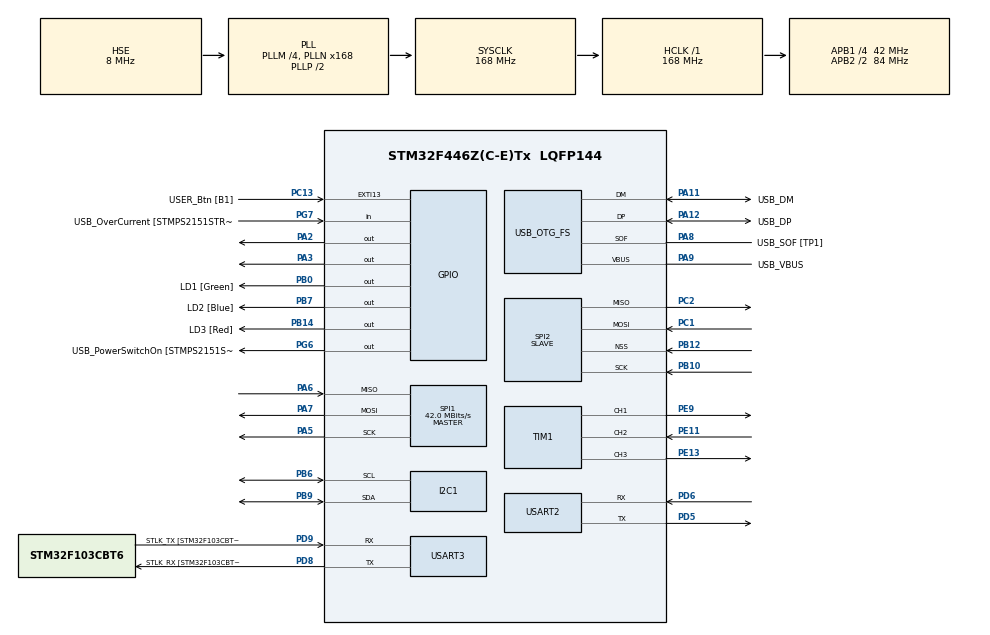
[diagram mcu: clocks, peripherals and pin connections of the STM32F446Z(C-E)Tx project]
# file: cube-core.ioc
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Dma.I2C1_RX.0.Direction=DMA_PERIPH_TO_MEMORY
Dma.I2C1_RX.0.FIFOMode=DMA_FIFOMODE_DISABLE
Dma.I2C1_RX.0.Instance=DMA1_Stream0
Dma.I2C1_RX.0.MemDataAlignment=DMA_MDATAALIGN_BYTE
Dma.I2C1_RX.0.MemInc=DMA_MINC_ENABLE
Dma.I2C1_RX.0.Mode=DMA_NORMAL
Dma.I2C1_RX.0.PeriphDataAlignment=DMA_PDATAALIGN_BYTE
Dma.I2C1_RX.0.PeriphInc=DMA_PINC_DISABLE
Dma.I2C1_RX.0.Priority=DMA_PRIORITY_LOW
Dma.I2C1_TX.1.Direction=DMA_MEMORY_TO_PERIPH
Dma.I2C1_TX.1.FIFOMode=DMA_FIFOMODE_DISABLE
Dma.I2C1_TX.1.Instance=DMA1_Stream7
Dma.I2C1_TX.1.MemDataAlignment=DMA_MDATAALIGN_BYTE
Dma.I2C1_TX.1.MemInc=DMA_MINC_ENABLE
Dma.I2C1_TX.1.Mode=DMA_NORMAL
Dma.I2C1_TX.1.PeriphDataAlignment=DMA_PDATAALIGN_BYTE
Dma.I2C1_TX.1.PeriphInc=DMA_PINC_DISABLE
Dma.I2C1_TX.1.Priority=DMA_PRIORITY_LOW
Dma.Request0=I2C1_RX
Dma.Request1=I2C1_TX
Dma.Request2=SPI1_RX
Dma.Request3=SPI1_TX
Dma.Request4=SPI2_RX
Dma.Request5=SPI2_TX
Dma.Request6=USART2_RX
Dma.Request7=USART2_TX
Dma.SPI1_RX.2.Direction=DMA_PERIPH_TO_MEMORY
Dma.SPI1_RX.2.FIFOMode=DMA_FIFOMODE_DISABLE
Dma.SPI1_RX.2.Instance=DMA2_Stream0
Dma.SPI1_RX.2.MemDataAlignment=DMA_MDATAALIGN_BYTE
Dma.SPI1_RX.2.MemInc=DMA_MINC_ENABLE
Dma.SPI1_RX.2.Mode=DMA_NORMAL
Dma.SPI1_RX.2.PeriphDataAlignment=DMA_PDATAALIGN_BYTE
Dma.SPI1_RX.2.PeriphInc=DMA_PINC_DISABLE
Dma.SPI1_RX.2.Priority=DMA_PRIORITY_LOW
Dma.SPI1_TX.3.Direction=DMA_MEMORY_TO_PERIPH
Dma.SPI1_TX.3.FIFOMode=DMA_FIFOMODE_DISABLE
Dma.SPI1_TX.3.Instance=DMA2_Stream3
Dma.SPI1_TX.3.MemDataAlignment=DMA_MDATAALIGN_BYTE
Dma.SPI1_TX.3.MemInc=DMA_MINC_ENABLE
Dma.SPI1_TX.3.Mode=DMA_NORMAL
Dma.SPI1_TX.3.PeriphDataAlignment=DMA_PDATAALIGN_BYTE
Dma.SPI1_TX.3.PeriphInc=DMA_PINC_DISABLE
Dma.SPI1_TX.3.Priority=DMA_PRIORITY_LOW
Dma.SPI2_RX.4.Direction=DMA_PERIPH_TO_MEMORY
Dma.SPI2_RX.4.FIFOMode=DMA_FIFOMODE_DISABLE
Dma.SPI2_RX.4.Instance=DMA1_Stream3
Dma.SPI2_RX.4.MemDataAlignment=DMA_MDATAALIGN_BYTE
Dma.SPI2_RX.4.MemInc=DMA_MINC_ENABLE
Dma.SPI2_RX.4.Mode=DMA_NORMAL
Dma.SPI2_RX.4.PeriphDataAlignment=DMA_PDATAALIGN_BYTE
Dma.SPI2_RX.4.PeriphInc=DMA_PINC_DISABLE
Dma.SPI2_RX.4.Priority=DMA_PRIORITY_LOW
Dma.SPI2_TX.5.Direction=DMA_MEMORY_TO_PERIPH
Dma.SPI2_TX.5.FIFOMode=DMA_FIFOMODE_DISABLE
Dma.SPI2_TX.5.Instance=DMA1_Stream4
Dma.SPI2_TX.5.MemDataAlignment=DMA_MDATAALIGN_BYTE
Dma.SPI2_TX.5.MemInc=DMA_MINC_ENABLE
Dma.SPI2_TX.5.Mode=DMA_NORMAL
Dma.SPI2_TX.5.PeriphDataAlignment=DMA_PDATAALIGN_BYTE
Dma.SPI2_TX.5.PeriphInc=DMA_PINC_DISABLE
Dma.SPI2_TX.5.Priority=DMA_PRIORITY_LOW
Dma.USART2_RX.6.Direction=DMA_PERIPH_TO_MEMORY
Dma.USART2_RX.6.FIFOMode=DMA_FIFOMODE_DISABLE
Dma.USART2_RX.6.Instance=DMA1_Stream5
Dma.USART2_RX.6.MemDataAlignment=DMA_MDATAALIGN_BYTE
Dma.USART2_RX.6.MemInc=DMA_MINC_ENABLE
Dma.USART2_RX.6.Mode=DMA_NORMAL
Dma.USART2_RX.6.PeriphDataAlignment=DMA_PDATAALIGN_BYTE
Dma.USART2_RX.6.PeriphInc=DMA_PINC_DISABLE
Dma.USART2_RX.6.Priority=DMA_PRIORITY_LOW
Dma.USART2_TX.7.Direction=DMA_MEMORY_TO_PERIPH
Dma.USART2_TX.7.FIFOMode=DMA_FIFOMODE_DISABLE
Dma.USART2_TX.7.Instance=DMA1_Stream6
Dma.USART2_TX.7.MemDataAlignment=DMA_MDATAALIGN_BYTE
Dma.USART2_TX.7.MemInc=DMA_MINC_ENABLE
Dma.USART2_TX.7.Mode=DMA_NORMAL
Dma.USART2_TX.7.PeriphDataAlignment=DMA_PDATAALIGN_BYTE
Dma.USART2_TX.7.PeriphInc=DMA_PINC_DISABLE
Dma.USART2_TX.7.Priority=DMA_PRIORITY_LOW
FREERTOS.Tasks01=defaultTask,24,3000,StartDefaultTask,Default,NULL,Static,defaultTaskBuffer,defaultTaskControlBlock;myTask02,24,3000,StartTask02,Default,NULL,Static,myTask02Buffer,myTask02ControlBlock
Mcu.Family=STM32F4
Mcu.Name=STM32F446Z(C-E)Tx
Mcu.Package=LQFP144
NVIC.DMA1_Stream0_IRQn=true\:5\:0\:false\:false\:true\:true\:false\:true
NVIC.DMA1_Stream3_IRQn=true\:5\:0\:false\:false\:true\:true\:false\:true
NVIC.DMA1_Stream4_IRQn=true\:5\:0\:false\:false\:true\:true\:false\:true
NVIC.DMA1_Stream5_IRQn=true\:5\:0\:false\:false\:true\:true\:false\:true
NVIC.DMA1_Stream6_IRQn=true\:5\:0\:false\:false\:true\:true\:false\:true
NVIC.DMA1_Stream7_IRQn=true\:5\:0\:false\:false\:true\:false\:false\:true
NVIC.DMA2_Stream0_IRQn=true\:5\:0\:false\:false\:true\:true\:false\:true
NVIC.DMA2_Stream3_IRQn=true\:5\:0\:false\:false\:true\:true\:false\:true
NVIC.I2C1_EV_IRQn=true\:5\:0\:false\:false\:true\:true\:true\:true
NVIC.PriorityGroup=NVIC_PRIORITYGROUP_4
NVIC.SPI1_IRQn=true\:5\:0\:false\:false\:true\:true\:true\:true
NVIC.SPI2_IRQn=true\:5\:0\:false\:false\:true\:true\:true\:true
NVIC.TIM1_CC_IRQn=true\:5\:0\:false\:false\:true\:true\:true\:true
NVIC.TIM1_UP_TIM10_IRQn=true\:5\:0\:false\:false\:true\:true\:true\:true
NVIC.TIM8_BRK_TIM12_IRQn=true\:0\:0\:false\:false\:true\:false\:false\:true
NVIC.TimeBase=TIM8_BRK_TIM12_IRQn
NVIC.TimeBaseIP=TIM12
NVIC.USART2_IRQn=true\:5\:0\:false\:false\:true\:true\:true\:true
NVIC.USART3_IRQn=true\:5\:0\:false\:false\:true\:true\:true\:true
PA10.GPIO_Label=USB_ID
PA10.Signal=USB_OTG_FS_ID
PA11.GPIO_Label=USB_DM
PA11.Mode=Device_Only
PA11.Signal=USB_OTG_FS_DM
PA12.GPIO_Label=USB_DP
PA12.Mode=Device_Only
PA12.Signal=USB_OTG_FS_DP
PA13.GPIO_Label=TMS
PA13.Mode=Serial_Wire
PA13.Signal=SYS_JTMS-SWDIO
PA14.GPIO_Label=TCK
PA14.Mode=Serial_Wire
PA14.Signal=SYS_JTCK-SWCLK
PA2.Signal=GPIO_Output
PA3.Signal=GPIO_Output
PA5.Mode=Full_Duplex_Master
PA5.Signal=SPI1_SCK
PA6.Mode=Full_Duplex_Master
PA6.Signal=SPI1_MISO
PA7.Mode=Full_Duplex_Master
PA7.Signal=SPI1_MOSI
PA8.GPIO_Label=USB_SOF [TP1]
PA8.Mode=Activate_SOF_FS
PA8.Signal=USB_OTG_FS_SOF
PA9.GPIO_Label=USB_VBUS
PA9.Mode=Activate_VBUS
PA9.Signal=USB_OTG_FS_VBUS
PB0.GPIO_Label=LD1 [Green]
PB0.Signal=GPIO_Output
PB10.Mode=Full_Duplex_Slave
PB10.Signal=SPI2_SCK
PB12.Mode=NSS_Signal_Hard_Input
PB12.Signal=SPI2_NSS
PB14.GPIO_Label=LD3 [Red]
PB14.Signal=GPIO_Output
PB6.Mode=I2C
PB6.Signal=I2C1_SCL
PB7.GPIO_Label=LD2 [Blue]
PB7.Signal=GPIO_Output
PB9.Mode=I2C
PB9.Signal=I2C1_SDA
PC1.Mode=Full_Duplex_Slave
PC1.Signal=SPI2_MOSI
PC13.GPIO_Label=USER_Btn [B1]
PC13.Signal=GPXTI13
PC14-OSC32_IN.Mode=LSE-External-Oscillator
PC14-OSC32_IN.Signal=RCC_OSC32_IN
PC15-OSC32_OUT.Mode=LSE-External-Oscillator
PC15-OSC32_OUT.Signal=RCC_OSC32_OUT
PC2.Mode=Full_Duplex_Slave
PC2.Signal=SPI2_MISO
PD5.Mode=Asynchronous
PD5.Signal=USART2_TX
PD6.Mode=Asynchronous
PD6.Signal=USART2_RX
PD8.GPIO_Label=STLK_RX [STM32F103CBT6_PA3]
PD8.Mode=Asynchronous
PD8.Signal=USART3_TX
PD9.GPIO_Label=STLK_TX [STM32F103CBT6_PA2]
PD9.Mode=Asynchronous
PD9.Signal=USART3_RX
PE11.Signal=S_TIM1_CH2
PE13.Signal=S_TIM1_CH3
PE9.Signal=S_TIM1_CH1
PG6.GPIO_Label=USB_PowerSwitchOn [STMPS2151STR_EN]
PG6.Signal=GPIO_Output
PG7.GPIO_Label=USB_OverCurrent [STMPS2151STR_FAULT]
PG7.Signal=GPIO_Input
PH0-OSC_IN.GPIO_Label=MCO [STM32F103CBT6_PA8]
PH0-OSC_IN.Mode=HSE-External-Clock-Source
PH0-OSC_IN.Signal=RCC_OSC_IN
PH1-OSC_OUT.Mode=HSE-External-Clock-Source
PH1-OSC_OUT.Signal=RCC_OSC_OUT
ProjectManager.HeapSize=0x200
ProjectManager.StackSize=0x400
ProjectManager.TargetToolchain=Makefile
RCC.48MHZClocksFreq_Value=24000000
RCC.AHBFreq_Value=168000000
RCC.APB1CLKDivider=RCC_HCLK_DIV4
RCC.APB1Freq_Value=42000000
RCC.APB1TimFreq_Value=84000000
RCC.APB2CLKDivider=RCC_HCLK_DIV2
RCC.APB2Freq_Value=84000000
RCC.APB2TimFreq_Value=168000000
RCC.CortexFreq_Value=168000000
RCC.HCLKFreq_Value=168000000
RCC.HSE_VALUE=8000000
RCC.HSI_VALUE=16000000
RCC.PLLM=4
RCC.PLLMUL=RCC_PLL_MUL9
RCC.PLLN=168
RCC.PLLQ=7
RCC.PRESCALERUSB=RCC_USBCLKSOURCE_PLL_DIV1_5
RCC.SYSCLKFreq_VALUE=168000000
RCC.SYSCLKSource=RCC_SYSCLKSOURCE_PLLCLK
RCC.SYSCLKSourceVirtual=RCC_SYSCLKSOURCE_PLLCLK
RCC.USBFreq_Value=48000000
RCC.VCOOutputFreq_Value=336000000
SH.S_TIM1_CH1.0=TIM1_CH1,PWM Generation1 CH1
SH.S_TIM1_CH2.0=TIM1_CH2,Input_Capture2_from_TI2
SH.S_TIM1_CH3.0=TIM1_CH3,PWM Generation3 CH3
SPI1.CalculateBaudRate=42.0 MBits/s
SPI1.Direction=SPI_DIRECTION_2LINES
SPI1.FirstBit=SPI_FIRSTBIT_MSB
SPI1.Mode=SPI_MODE_MASTER
SPI1.VirtualType=VM_MASTER
SPI2.Direction=SPI_DIRECTION_2LINES
SPI2.Mode=SPI_MODE_SLAVE
SPI2.VirtualNSS=VM_NSSHARD
SPI2.VirtualType=VM_SLAVE
TIM1.Channel-Input_Capture2_from_TI2=TIM_CHANNEL_2
TIM1.Channel-PWM\ Generation1\ CH1=TIM_CHANNEL_1
TIM1.Channel-PWM\ Generation3\ CH3=TIM_CHANNEL_3
USART2.VirtualMode=VM_ASYNC
USART3.VirtualMode=VM_ASYNC
USB_OTG_FS.VirtualMode=Device_Only
VP_FREERTOS_VS_CMSIS_V2.Mode=CMSIS_V2
VP_SYS_VS_tim12.Mode=TIM12
VP_TIM10_VS_ClockSourceINT.Mode=Enable_Timer
board=NUCLEO-F446ZE

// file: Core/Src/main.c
/* USER CODE BEGIN Header */
/**
  ******************************************************************************
  * @file           : main.c
  * @brief          : Main program body
  ******************************************************************************
  * @attention
  *
  * <h2><center>&copy; Copyright (c) 2020 STMicroelectronics.
  * All rights reserved.</center></h2>
  *
  * This software component is licensed by ST under Ultimate Liberty license
  * SLA0044, the "License"; You may not use this file except in compliance with
  * the License. You may obtain a copy of the License at:
  *                             www.st.com/SLA0044
  *
  ******************************************************************************
  */
/* USER CODE END Header */

#include "main.h"
#include "cmsis_os.h"

I2C_HandleTypeDef hi2c1;
DMA_HandleTypeDef hdma_i2c1_rx;
DMA_HandleTypeDef hdma_i2c1_tx;

SPI_HandleTypeDef hspi1;
SPI_HandleTypeDef hspi2;
DMA_HandleTypeDef hdma_spi1_rx;
DMA_HandleTypeDef hdma_spi1_tx;
DMA_HandleTypeDef hdma_spi2_rx;
DMA_HandleTypeDef hdma_spi2_tx;

TIM_HandleTypeDef htim1;
TIM_HandleTypeDef htim10;

UART_HandleTypeDef huart2;
UART_HandleTypeDef huart3;
DMA_HandleTypeDef hdma_usart2_rx;
DMA_HandleTypeDef hdma_usart2_tx;

PCD_HandleTypeDef hpcd_USB_OTG_FS;

typedef StaticTask_t osStaticThreadDef_t;
osThreadId_t defaultTaskHandle;
uint32_t defaultTaskBuffer[ 3000 ];
osStaticThreadDef_t defaultTaskControlBlock;
osThreadId_t myTask02Handle;
uint32_t myTask02Buffer[ 3000 ];
osStaticThreadDef_t myTask02ControlBlock;

void SystemClock_Config(void);
static void MX_GPIO_Init(void);
static void MX_DMA_Init(void);
static void MX_USART3_UART_Init(void);
static void MX_USB_OTG_FS_PCD_Init(void);
static void MX_I2C1_Init(void);
static void MX_SPI1_Init(void);
static void MX_SPI2_Init(void);
static void MX_TIM1_Init(void);
static void MX_TIM10_Init(void);
static void MX_USART2_UART_Init(void);
void StartDefaultTask(void *argument);
void StartTask02(void *argument);

int main(void)
{

  /* MCU Configuration--------------------------------------------------------*/

  /* Reset of all peripherals, Initializes the Flash interface and the Systick. */
  HAL_Init();

  /* Configure the system clock */
  SystemClock_Config();

  /* Initialize all configured peripherals */
  MX_GPIO_Init();
  MX_DMA_Init();
  MX_USART3_UART_Init();
  MX_USB_OTG_FS_PCD_Init();
  MX_I2C1_Init();
  MX_SPI1_Init();
  MX_SPI2_Init();
  MX_TIM1_Init();
  MX_TIM10_Init();
  MX_USART2_UART_Init();
  /* USER CODE BEGIN 2 */
  setup();
  /* USER CODE END 2 */

  osKernelInitialize();

  /* Create the thread(s) */
  /* definition and creation of defaultTask */
  const osThreadAttr_t defaultTask_attributes = {
    .name = "defaultTask",
    .stack_mem = &defaultTaskBuffer[0],
    .stack_size = sizeof(defaultTaskBuffer),
    .cb_mem = &defaultTaskControlBlock,
    .cb_size = sizeof(defaultTaskControlBlock),
    .priority = (osPriority_t) osPriorityNormal,
  };
  defaultTaskHandle = osThreadNew(StartDefaultTask, NULL, &defaultTask_attributes);

  /* definition and creation of myTask02 */
  const osThreadAttr_t myTask02_attributes = {
    .name = "myTask02",
    .stack_mem = &myTask02Buffer[0],
    .stack_size = sizeof(myTask02Buffer),
    .cb_mem = &myTask02ControlBlock,
    .cb_size = sizeof(myTask02ControlBlock),
    .priority = (osPriority_t) osPriorityNormal,
  };
  myTask02Handle = osThreadNew(StartTask02, NULL, &myTask02_attributes);

  /* Start scheduler */
  osKernelStart();

  /* We should never get here as control is now taken by the scheduler */

  /* Infinite loop */
  while (1)
  {

  }
}

void SystemClock_Config(void)
{
  RCC_OscInitTypeDef RCC_OscInitStruct = {0};
  RCC_ClkInitTypeDef RCC_ClkInitStruct = {0};
  RCC_PeriphCLKInitTypeDef PeriphClkInitStruct = {0};

  /** Configure the main internal regulator output voltage
  */
  __HAL_RCC_PWR_CLK_ENABLE();
  __HAL_PWR_VOLTAGESCALING_CONFIG(PWR_REGULATOR_VOLTAGE_SCALE1);
  /** Initializes the CPU, AHB and APB busses clocks
  */
  RCC_OscInitStruct.OscillatorType = RCC_OSCILLATORTYPE_HSE;
  RCC_OscInitStruct.HSEState = RCC_HSE_BYPASS;
  RCC_OscInitStruct.PLL.PLLState = RCC_PLL_ON;
  RCC_OscInitStruct.PLL.PLLSource = RCC_PLLSOURCE_HSE;
  RCC_OscInitStruct.PLL.PLLM = 4;
  RCC_OscInitStruct.PLL.PLLN = 168;
  RCC_OscInitStruct.PLL.PLLP = RCC_PLLP_DIV2;
  RCC_OscInitStruct.PLL.PLLQ = 7;
  RCC_OscInitStruct.PLL.PLLR = 2;
  if (HAL_RCC_OscConfig(&RCC_OscInitStruct) != HAL_OK)
  {
    Error_Handler();
  }
  /** Initializes the CPU, AHB and APB busses clocks
  */
  RCC_ClkInitStruct.ClockType = RCC_CLOCKTYPE_HCLK|RCC_CLOCKTYPE_SYSCLK
                              |RCC_CLOCKTYPE_PCLK1|RCC_CLOCKTYPE_PCLK2;
  RCC_ClkInitStruct.SYSCLKSource = RCC_SYSCLKSOURCE_PLLCLK;
  RCC_ClkInitStruct.AHBCLKDivider = RCC_SYSCLK_DIV1;
  RCC_ClkInitStruct.APB1CLKDivider = RCC_HCLK_DIV4;
  RCC_ClkInitStruct.APB2CLKDivider = RCC_HCLK_DIV2;

  if (HAL_RCC_ClockConfig(&RCC_ClkInitStruct, FLASH_LATENCY_5) != HAL_OK)
  {
    Error_Handler();
  }
  PeriphClkInitStruct.PeriphClockSelection = RCC_PERIPHCLK_CLK48;
  PeriphClkInitStruct.Clk48ClockSelection = RCC_CLK48CLKSOURCE_PLLQ;
  if (HAL_RCCEx_PeriphCLKConfig(&PeriphClkInitStruct) != HAL_OK)
  {
    Error_Handler();
  }
}

static void MX_I2C1_Init(void)
{

  hi2c1.Instance = I2C1;
  hi2c1.Init.ClockSpeed = 100000;
  hi2c1.Init.DutyCycle = I2C_DUTYCYCLE_2;
  hi2c1.Init.OwnAddress1 = 0;
  hi2c1.Init.AddressingMode = I2C_ADDRESSINGMODE_7BIT;
  hi2c1.Init.DualAddressMode = I2C_DUALADDRESS_DISABLE;
  hi2c1.Init.OwnAddress2 = 0;
  hi2c1.Init.GeneralCallMode = I2C_GENERALCALL_DISABLE;
  hi2c1.Init.NoStretchMode = I2C_NOSTRETCH_DISABLE;
  if (HAL_I2C_Init(&hi2c1) != HAL_OK)
  {
    Error_Handler();
  }

}

static void MX_SPI1_Init(void)
{

  /* SPI1 parameter configuration*/
  hspi1.Instance = SPI1;
  hspi1.Init.Mode = SPI_MODE_MASTER;
  hspi1.Init.Direction = SPI_DIRECTION_2LINES;
  hspi1.Init.DataSize = SPI_DATASIZE_8BIT;
  hspi1.Init.CLKPolarity = SPI_POLARITY_LOW;
  hspi1.Init.CLKPhase = SPI_PHASE_1EDGE;
  hspi1.Init.NSS = SPI_NSS_SOFT;
  hspi1.Init.BaudRatePrescaler = SPI_BAUDRATEPRESCALER_2;
  hspi1.Init.FirstBit = SPI_FIRSTBIT_MSB;
  hspi1.Init.TIMode = SPI_TIMODE_DISABLE;
  hspi1.Init.CRCCalculation = SPI_CRCCALCULATION_DISABLE;
  hspi1.Init.CRCPolynomial = 10;
  if (HAL_SPI_Init(&hspi1) != HAL_OK)
  {
    Error_Handler();
  }

}

static void MX_SPI2_Init(void)
{

  /* SPI2 parameter configuration*/
  hspi2.Instance = SPI2;
  hspi2.Init.Mode = SPI_MODE_SLAVE;
  hspi2.Init.Direction = SPI_DIRECTION_2LINES;
  hspi2.Init.DataSize = SPI_DATASIZE_8BIT;
  hspi2.Init.CLKPolarity = SPI_POLARITY_LOW;
  hspi2.Init.CLKPhase = SPI_PHASE_1EDGE;
  hspi2.Init.NSS = SPI_NSS_HARD_INPUT;
  hspi2.Init.FirstBit = SPI_FIRSTBIT_MSB;
  hspi2.Init.TIMode = SPI_TIMODE_DISABLE;
  hspi2.Init.CRCCalculation = SPI_CRCCALCULATION_DISABLE;
  hspi2.Init.CRCPolynomial = 10;
  if (HAL_SPI_Init(&hspi2) != HAL_OK)
  {
    Error_Handler();
  }

}

static void MX_TIM1_Init(void)
{

  TIM_MasterConfigTypeDef sMasterConfig = {0};
  TIM_OC_InitTypeDef sConfigOC = {0};
  TIM_IC_InitTypeDef sConfigIC = {0};
  TIM_BreakDeadTimeConfigTypeDef sBreakDeadTimeConfig = {0};

  htim1.Instance = TIM1;
  htim1.Init.Prescaler = 0;
  htim1.Init.CounterMode = TIM_COUNTERMODE_UP;
  htim1.Init.Period = 0;
  htim1.Init.ClockDivision = TIM_CLOCKDIVISION_DIV1;
  htim1.Init.RepetitionCounter = 0;
  htim1.Init.AutoReloadPreload = TIM_AUTORELOAD_PRELOAD_DISABLE;
  if (HAL_TIM_PWM_Init(&htim1) != HAL_OK)
  {
    Error_Handler();
  }
  if (HAL_TIM_IC_Init(&htim1) != HAL_OK)
  {
    Error_Handler();
  }
  sMasterConfig.MasterOutputTrigger = TIM_TRGO_RESET;
  sMasterConfig.MasterSlaveMode = TIM_MASTERSLAVEMODE_DISABLE;
  if (HAL_TIMEx_MasterConfigSynchronization(&htim1, &sMasterConfig) != HAL_OK)
  {
    Error_Handler();
  }
  sConfigOC.OCMode = TIM_OCMODE_PWM1;
  sConfigOC.Pulse = 0;
  sConfigOC.OCPolarity = TIM_OCPOLARITY_HIGH;
  sConfigOC.OCNPolarity = TIM_OCNPOLARITY_HIGH;
  sConfigOC.OCFastMode = TIM_OCFAST_DISABLE;
  sConfigOC.OCIdleState = TIM_OCIDLESTATE_RESET;
  sConfigOC.OCNIdleState = TIM_OCNIDLESTATE_RESET;
  if (HAL_TIM_PWM_ConfigChannel(&htim1, &sConfigOC, TIM_CHANNEL_1) != HAL_OK)
  {
    Error_Handler();
  }
  sConfigIC.ICPolarity = TIM_INPUTCHANNELPOLARITY_RISING;
  sConfigIC.ICSelection = TIM_ICSELECTION_DIRECTTI;
  sConfigIC.ICPrescaler = TIM_ICPSC_DIV1;
  sConfigIC.ICFilter = 0;
  if (HAL_TIM_IC_ConfigChannel(&htim1, &sConfigIC, TIM_CHANNEL_2) != HAL_OK)
  {
    Error_Handler();
  }
  if (HAL_TIM_PWM_ConfigChannel(&htim1, &sConfigOC, TIM_CHANNEL_3) != HAL_OK)
  {
    Error_Handler();
  }
  sBreakDeadTimeConfig.OffStateRunMode = TIM_OSSR_DISABLE;
  sBreakDeadTimeConfig.OffStateIDLEMode = TIM_OSSI_DISABLE;
  sBreakDeadTimeConfig.LockLevel = TIM_LOCKLEVEL_OFF;
  sBreakDeadTimeConfig.DeadTime = 0;
  sBreakDeadTimeConfig.BreakState = TIM_BREAK_DISABLE;
  sBreakDeadTimeConfig.BreakPolarity = TIM_BREAKPOLARITY_HIGH;
  sBreakDeadTimeConfig.AutomaticOutput = TIM_AUTOMATICOUTPUT_DISABLE;
  if (HAL_TIMEx_ConfigBreakDeadTime(&htim1, &sBreakDeadTimeConfig) != HAL_OK)
  {
    Error_Handler();
  }
  HAL_TIM_MspPostInit(&htim1);

}

static void MX_TIM10_Init(void)
{

  htim10.Instance = TIM10;
  htim10.Init.Prescaler = 0;
  htim10.Init.CounterMode = TIM_COUNTERMODE_UP;
  htim10.Init.Period = 0;
  htim10.Init.ClockDivision = TIM_CLOCKDIVISION_DIV1;
  htim10.Init.AutoReloadPreload = TIM_AUTORELOAD_PRELOAD_DISABLE;
  if (HAL_TIM_Base_Init(&htim10) != HAL_OK)
  {
    Error_Handler();
  }

}

static void MX_USART2_UART_Init(void)
{

  huart2.Instance = USART2;
  huart2.Init.BaudRate = 115200;
  huart2.Init.WordLength = UART_WORDLENGTH_8B;
  huart2.Init.StopBits = UART_STOPBITS_1;
  huart2.Init.Parity = UART_PARITY_NONE;
  huart2.Init.Mode = UART_MODE_TX_RX;
  huart2.Init.HwFlowCtl = UART_HWCONTROL_NONE;
  huart2.Init.OverSampling = UART_OVERSAMPLING_16;
  if (HAL_UART_Init(&huart2) != HAL_OK)
  {
    Error_Handler();
  }

}

static void MX_USART3_UART_Init(void)
{

  huart3.Instance = USART3;
  huart3.Init.BaudRate = 115200;
  huart3.Init.WordLength = UART_WORDLENGTH_8B;
  huart3.Init.StopBits = UART_STOPBITS_1;
  huart3.Init.Parity = UART_PARITY_NONE;
  huart3.Init.Mode = UART_MODE_TX_RX;
  huart3.Init.HwFlowCtl = UART_HWCONTROL_NONE;
  huart3.Init.OverSampling = UART_OVERSAMPLING_16;
  if (HAL_UART_Init(&huart3) != HAL_OK)
  {
    Error_Handler();
  }

}

static void MX_USB_OTG_FS_PCD_Init(void)
{

  hpcd_USB_OTG_FS.Instance = USB_OTG_FS;
  hpcd_USB_OTG_FS.Init.dev_endpoints = 6;
  hpcd_USB_OTG_FS.Init.speed = PCD_SPEED_FULL;
  hpcd_USB_OTG_FS.Init.dma_enable = DISABLE;
  hpcd_USB_OTG_FS.Init.phy_itface = PCD_PHY_EMBEDDED;
  hpcd_USB_OTG_FS.Init.Sof_enable = ENABLE;
  hpcd_USB_OTG_FS.Init.low_power_enable = DISABLE;
  hpcd_USB_OTG_FS.Init.lpm_enable = DISABLE;
  hpcd_USB_OTG_FS.Init.vbus_sensing_enable = ENABLE;
  hpcd_USB_OTG_FS.Init.use_dedicated_ep1 = DISABLE;
  if (HAL_PCD_Init(&hpcd_USB_OTG_FS) != HAL_OK)
  {
    Error_Handler();
  }

}

static void MX_DMA_Init(void)
{

  /* DMA controller clock enable */
  __HAL_RCC_DMA1_CLK_ENABLE();
  __HAL_RCC_DMA2_CLK_ENABLE();

  /* DMA interrupt init */
  /* DMA1_Stream0_IRQn interrupt configuration */
  HAL_NVIC_SetPriority(DMA1_Stream0_IRQn, 5, 0);
  HAL_NVIC_EnableIRQ(DMA1_Stream0_IRQn);
  /* DMA1_Stream3_IRQn interrupt configuration */
  HAL_NVIC_SetPriority(DMA1_Stream3_IRQn, 5, 0);
  HAL_NVIC_EnableIRQ(DMA1_Stream3_IRQn);
  /* DMA1_Stream4_IRQn interrupt configuration */
  HAL_NVIC_SetPriority(DMA1_Stream4_IRQn, 5, 0);
  HAL_NVIC_EnableIRQ(DMA1_Stream4_IRQn);
  /* DMA1_Stream5_IRQn interrupt configuration */
  HAL_NVIC_SetPriority(DMA1_Stream5_IRQn, 5, 0);
  HAL_NVIC_EnableIRQ(DMA1_Stream5_IRQn);
  /* DMA1_Stream6_IRQn interrupt configuration */
  HAL_NVIC_SetPriority(DMA1_Stream6_IRQn, 5, 0);
  HAL_NVIC_EnableIRQ(DMA1_Stream6_IRQn);
  /* DMA1_Stream7_IRQn interrupt configuration */
  HAL_NVIC_SetPriority(DMA1_Stream7_IRQn, 5, 0);
  HAL_NVIC_EnableIRQ(DMA1_Stream7_IRQn);
  /* DMA2_Stream0_IRQn interrupt configuration */
  HAL_NVIC_SetPriority(DMA2_Stream0_IRQn, 5, 0);
  HAL_NVIC_EnableIRQ(DMA2_Stream0_IRQn);
  /* DMA2_Stream3_IRQn interrupt configuration */
  HAL_NVIC_SetPriority(DMA2_Stream3_IRQn, 5, 0);
  HAL_NVIC_EnableIRQ(DMA2_Stream3_IRQn);

}

static void MX_GPIO_Init(void)
{
  GPIO_InitTypeDef GPIO_InitStruct = {0};

  /* GPIO Ports Clock Enable */
  __HAL_RCC_GPIOC_CLK_ENABLE();
  __HAL_RCC_GPIOH_CLK_ENABLE();
  __HAL_RCC_GPIOA_CLK_ENABLE();
  __HAL_RCC_GPIOB_CLK_ENABLE();
  __HAL_RCC_GPIOE_CLK_ENABLE();
  __HAL_RCC_GPIOD_CLK_ENABLE();
  __HAL_RCC_GPIOG_CLK_ENABLE();

  /*Configure GPIO pin Output Level */
  HAL_GPIO_WritePin(GPIOA, GPIO_PIN_2|GPIO_PIN_3, GPIO_PIN_RESET);

  /*Configure GPIO pin Output Level */
  HAL_GPIO_WritePin(GPIOB, LD1_Pin|LD3_Pin|LD2_Pin, GPIO_PIN_RESET);

  /*Configure GPIO pin Output Level */
  HAL_GPIO_WritePin(USB_PowerSwitchOn_GPIO_Port, USB_PowerSwitchOn_Pin, GPIO_PIN_RESET);

  /*Configure GPIO pin : USER_Btn_Pin */
  GPIO_InitStruct.Pin = USER_Btn_Pin;
  GPIO_InitStruct.Mode = GPIO_MODE_IT_RISING;
  GPIO_InitStruct.Pull = GPIO_NOPULL;
  HAL_GPIO_Init(USER_Btn_GPIO_Port, &GPIO_InitStruct);

  /*Configure GPIO pins : PA2 PA3 */
  GPIO_InitStruct.Pin = GPIO_PIN_2|GPIO_PIN_3;
  GPIO_InitStruct.Mode = GPIO_MODE_OUTPUT_PP;
  GPIO_InitStruct.Pull = GPIO_NOPULL;
  GPIO_InitStruct.Speed = GPIO_SPEED_FREQ_LOW;
  HAL_GPIO_Init(GPIOA, &GPIO_InitStruct);

  /*Configure GPIO pins : LD1_Pin LD3_Pin LD2_Pin */
  GPIO_InitStruct.Pin = LD1_Pin|LD3_Pin|LD2_Pin;
  GPIO_InitStruct.Mode = GPIO_MODE_OUTPUT_PP;
  GPIO_InitStruct.Pull = GPIO_NOPULL;
  GPIO_InitStruct.Speed = GPIO_SPEED_FREQ_LOW;
  HAL_GPIO_Init(GPIOB, &GPIO_InitStruct);

  /*Configure GPIO pin : USB_PowerSwitchOn_Pin */
  GPIO_InitStruct.Pin = USB_PowerSwitchOn_Pin;
  GPIO_InitStruct.Mode = GPIO_MODE_OUTPUT_PP;
  GPIO_InitStruct.Pull = GPIO_NOPULL;
  GPIO_InitStruct.Speed = GPIO_SPEED_FREQ_LOW;
  HAL_GPIO_Init(USB_PowerSwitchOn_GPIO_Port, &GPIO_InitStruct);

  /*Configure GPIO pin : USB_OverCurrent_Pin */
  GPIO_InitStruct.Pin = USB_OverCurrent_Pin;
  GPIO_InitStruct.Mode = GPIO_MODE_INPUT;
  GPIO_InitStruct.Pull = GPIO_NOPULL;
  HAL_GPIO_Init(USB_OverCurrent_GPIO_Port, &GPIO_InitStruct);

}

void StartDefaultTask(void *argument)
{
  /* USER CODE BEGIN 5 */
  /* Infinite loop */
  for(;;)
  {
    loop1();
    osDelay(1);
  }
  /* USER CODE END 5 */
}

void StartTask02(void *argument)
{
  /* USER CODE BEGIN StartTask02 */
  /* Infinite loop */
  for(;;)
  {
    loop0();
    osDelay(1);
  }
  /* USER CODE END StartTask02 */
}

void HAL_TIM_PeriodElapsedCallback(TIM_HandleTypeDef *htim)
{
  if (htim->Instance == TIM12) {
    HAL_IncTick();
  }
}

void Error_Handler(void)
{
}

/************************ (C) COPYRIGHT STMicroelectronics *****END OF FILE****/
